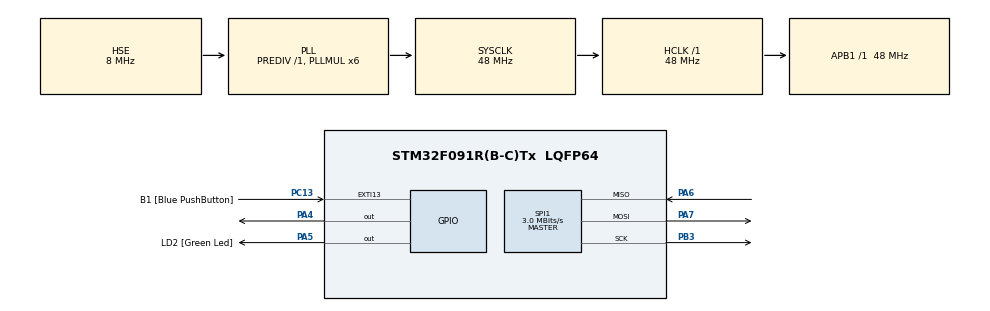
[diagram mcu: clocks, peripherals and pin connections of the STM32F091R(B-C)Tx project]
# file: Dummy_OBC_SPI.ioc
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Mcu.Family=STM32F0
Mcu.Name=STM32F091R(B-C)Tx
Mcu.Package=LQFP64
PA13.GPIO_Label=TMS
PA13.Signal=SYS_SWDIO
PA14.GPIO_Label=TCK
PA14.Signal=SYS_SWCLK
PA2.GPIO_Label=USART_TX
PA2.GPIO_Mode=GPIO_MODE_AF_PP
PA2.GPIO_PuPd=GPIO_NOPULL
PA2.GPIO_Speed=GPIO_SPEED_FREQ_LOW
PA2.Signal=USART2_TX
PA3.GPIO_Label=USART_RX
PA3.GPIO_Mode=GPIO_MODE_AF_PP
PA3.GPIO_PuPd=GPIO_NOPULL
PA3.GPIO_Speed=GPIO_SPEED_FREQ_LOW
PA3.Signal=USART2_RX
PA4.Signal=GPIO_Output
PA5.GPIO_Label=LD2 [Green Led]
PA5.GPIO_Mode=GPIO_MODE_OUTPUT_PP
PA5.GPIO_PuPd=GPIO_NOPULL
PA5.GPIO_Speed=GPIO_SPEED_FREQ_LOW
PA5.Signal=GPIO_Output
PA6.Mode=Full_Duplex_Master
PA6.Signal=SPI1_MISO
PA7.Mode=Full_Duplex_Master
PA7.Signal=SPI1_MOSI
PB3.Mode=Full_Duplex_Master
PB3.Signal=SPI1_SCK
PC13.GPIO_Label=B1 [Blue PushButton]
PC13.GPIO_ModeDefaultEXTI=GPIO_MODE_IT_FALLING
PC13.Signal=GPXTI13
PC14OSC32_IN.Signal=RCC_OSC32_IN
PC15OSC32_OUT.Signal=RCC_OSC32_OUT
PF0-OSC_IN.Mode=HSE-External-Oscillator
PF0-OSC_IN.Signal=RCC_OSC_IN
PF1-OSC_OUT.Mode=HSE-External-Oscillator
PF1-OSC_OUT.Signal=RCC_OSC_OUT
ProjectManager.HeapSize=0x200
ProjectManager.StackSize=0x400
ProjectManager.TargetToolchain=STM32CubeIDE
RCC.AHBFreq_Value=48000000
RCC.APB1Freq_Value=48000000
RCC.APB1TimFreq_Value=48000000
RCC.FLatency-AdvancedSettings=FLASH_LATENCY_1
RCC.HCLKFreq_Value=48000000
RCC.PLLMUL=RCC_PLL_MUL6
RCC.PLLSourceVirtual=RCC_PLLSOURCE_HSE
RCC.PREFETCH_ENABLE-AdvancedSettings=1
RCC.SYSCLKFreq_VALUE=48000000
RCC.SYSCLKSource=RCC_SYSCLKSOURCE_PLLCLK
SPI1.BaudRatePrescaler=SPI_BAUDRATEPRESCALER_16
SPI1.CalculateBaudRate=3.0 MBits/s
SPI1.DataSize=SPI_DATASIZE_8BIT
SPI1.Direction=SPI_DIRECTION_2LINES
SPI1.Mode=SPI_MODE_MASTER
SPI1.NSSPMode=SPI_NSS_PULSE_DISABLE
SPI1.VirtualType=VM_MASTER
board=NUCLEO-F091RC

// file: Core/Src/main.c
/* USER CODE BEGIN Header */
/**
  ******************************************************************************
  * @file           : main.c
  * @brief          : Main program body
  ******************************************************************************
  * @attention
  *
  * Copyright (c) 2022 STMicroelectronics.
  * All rights reserved.
  *
  * This software is licensed under terms that can be found in the LICENSE file
  * in the root directory of this software component.
  * If no LICENSE file comes with this software, it is provided AS-IS.
  *
  ******************************************************************************
  */
/* USER CODE END Header */
#include "main.h"

SPI_HandleTypeDef hspi1;

/* USER CODE BEGIN PV */
uint8_t buffer_tx[15]={1,2,3,4,5,6,7,8,9,10,11,12,13,14,15};
uint8_t buffer_rx[15];
/* USER CODE END PV */

void SystemClock_Config(void);
static void MX_GPIO_Init(void);
static void MX_SPI1_Init(void);

int main(void)
{

  /* MCU Configuration--------------------------------------------------------*/

  /* Reset of all peripherals, Initializes the Flash interface and the Systick. */
  HAL_Init();

  /* Configure the system clock */
  SystemClock_Config();

  /* Initialize all configured peripherals */
  MX_GPIO_Init();
  MX_SPI1_Init();
  /* USER CODE BEGIN 2 */
HAL_GPIO_WritePin(GPIOA,GPIO_PIN_4,SET);

//Begin Transmission
HAL_GPIO_WritePin(GPIOA,GPIO_PIN_4,RESET);
HAL_SPI_Transmit(&hspi1, buffer_tx,sizeof(buffer_tx),100);
HAL_GPIO_WritePin(GPIOA,GPIO_PIN_4,SET);
HAL_Delay(100);
HAL_GPIO_WritePin(GPIOA,GPIO_PIN_4,RESET);
HAL_SPI_Transmit(&hspi1, buffer_rx,sizeof(buffer_rx),100);
HAL_GPIO_WritePin(GPIOA,GPIO_PIN_4,SET);
  /* USER CODE END 2 */

  /* Infinite loop */
  while (1)
  {

  }
}

void SystemClock_Config(void)
{
  RCC_OscInitTypeDef RCC_OscInitStruct = {0};
  RCC_ClkInitTypeDef RCC_ClkInitStruct = {0};

  /** Initializes the RCC Oscillators according to the specified parameters
  * in the RCC_OscInitTypeDef structure.
  */
  RCC_OscInitStruct.OscillatorType = RCC_OSCILLATORTYPE_HSE;
  RCC_OscInitStruct.HSEState = RCC_HSE_ON;
  RCC_OscInitStruct.PLL.PLLState = RCC_PLL_ON;
  RCC_OscInitStruct.PLL.PLLSource = RCC_PLLSOURCE_HSE;
  RCC_OscInitStruct.PLL.PLLMUL = RCC_PLL_MUL6;
  RCC_OscInitStruct.PLL.PREDIV = RCC_PREDIV_DIV1;
  if (HAL_RCC_OscConfig(&RCC_OscInitStruct) != HAL_OK)
  {
    Error_Handler();
  }
  /** Initializes the CPU, AHB and APB buses clocks
  */
  RCC_ClkInitStruct.ClockType = RCC_CLOCKTYPE_HCLK|RCC_CLOCKTYPE_SYSCLK
                              |RCC_CLOCKTYPE_PCLK1;
  RCC_ClkInitStruct.SYSCLKSource = RCC_SYSCLKSOURCE_PLLCLK;
  RCC_ClkInitStruct.AHBCLKDivider = RCC_SYSCLK_DIV1;
  RCC_ClkInitStruct.APB1CLKDivider = RCC_HCLK_DIV1;

  if (HAL_RCC_ClockConfig(&RCC_ClkInitStruct, FLASH_LATENCY_1) != HAL_OK)
  {
    Error_Handler();
  }
}

static void MX_SPI1_Init(void)
{

  /* SPI1 parameter configuration*/
  hspi1.Instance = SPI1;
  hspi1.Init.Mode = SPI_MODE_MASTER;
  hspi1.Init.Direction = SPI_DIRECTION_2LINES;
  hspi1.Init.DataSize = SPI_DATASIZE_8BIT;
  hspi1.Init.CLKPolarity = SPI_POLARITY_LOW;
  hspi1.Init.CLKPhase = SPI_PHASE_1EDGE;
  hspi1.Init.NSS = SPI_NSS_SOFT;
  hspi1.Init.BaudRatePrescaler = SPI_BAUDRATEPRESCALER_16;
  hspi1.Init.FirstBit = SPI_FIRSTBIT_MSB;
  hspi1.Init.TIMode = SPI_TIMODE_DISABLE;
  hspi1.Init.CRCCalculation = SPI_CRCCALCULATION_DISABLE;
  hspi1.Init.CRCPolynomial = 7;
  hspi1.Init.CRCLength = SPI_CRC_LENGTH_DATASIZE;
  hspi1.Init.NSSPMode = SPI_NSS_PULSE_DISABLE;
  if (HAL_SPI_Init(&hspi1) != HAL_OK)
  {
    Error_Handler();
  }

}

static void MX_GPIO_Init(void)
{
  GPIO_InitTypeDef GPIO_InitStruct = {0};

  /* GPIO Ports Clock Enable */
  __HAL_RCC_GPIOC_CLK_ENABLE();
  __HAL_RCC_GPIOF_CLK_ENABLE();
  __HAL_RCC_GPIOA_CLK_ENABLE();
  __HAL_RCC_GPIOB_CLK_ENABLE();

  /*Configure GPIO pin Output Level */
  HAL_GPIO_WritePin(GPIOA, GPIO_PIN_4|LD2_Pin, GPIO_PIN_RESET);

  /*Configure GPIO pin : B1_Pin */
  GPIO_InitStruct.Pin = B1_Pin;
  GPIO_InitStruct.Mode = GPIO_MODE_IT_FALLING;
  GPIO_InitStruct.Pull = GPIO_NOPULL;
  HAL_GPIO_Init(B1_GPIO_Port, &GPIO_InitStruct);

  /*Configure GPIO pins : USART_TX_Pin USART_RX_Pin */
  GPIO_InitStruct.Pin = USART_TX_Pin|USART_RX_Pin;
  GPIO_InitStruct.Mode = GPIO_MODE_AF_PP;
  GPIO_InitStruct.Pull = GPIO_NOPULL;
  GPIO_InitStruct.Speed = GPIO_SPEED_FREQ_LOW;
  GPIO_InitStruct.Alternate = GPIO_AF1_USART2;
  HAL_GPIO_Init(GPIOA, &GPIO_InitStruct);

  /*Configure GPIO pins : PA4 LD2_Pin */
  GPIO_InitStruct.Pin = GPIO_PIN_4|LD2_Pin;
  GPIO_InitStruct.Mode = GPIO_MODE_OUTPUT_PP;
  GPIO_InitStruct.Pull = GPIO_NOPULL;
  GPIO_InitStruct.Speed = GPIO_SPEED_FREQ_LOW;
  HAL_GPIO_Init(GPIOA, &GPIO_InitStruct);

}

void Error_Handler(void)
{
  __disable_irq();
  while (1)
  {
  }
}
